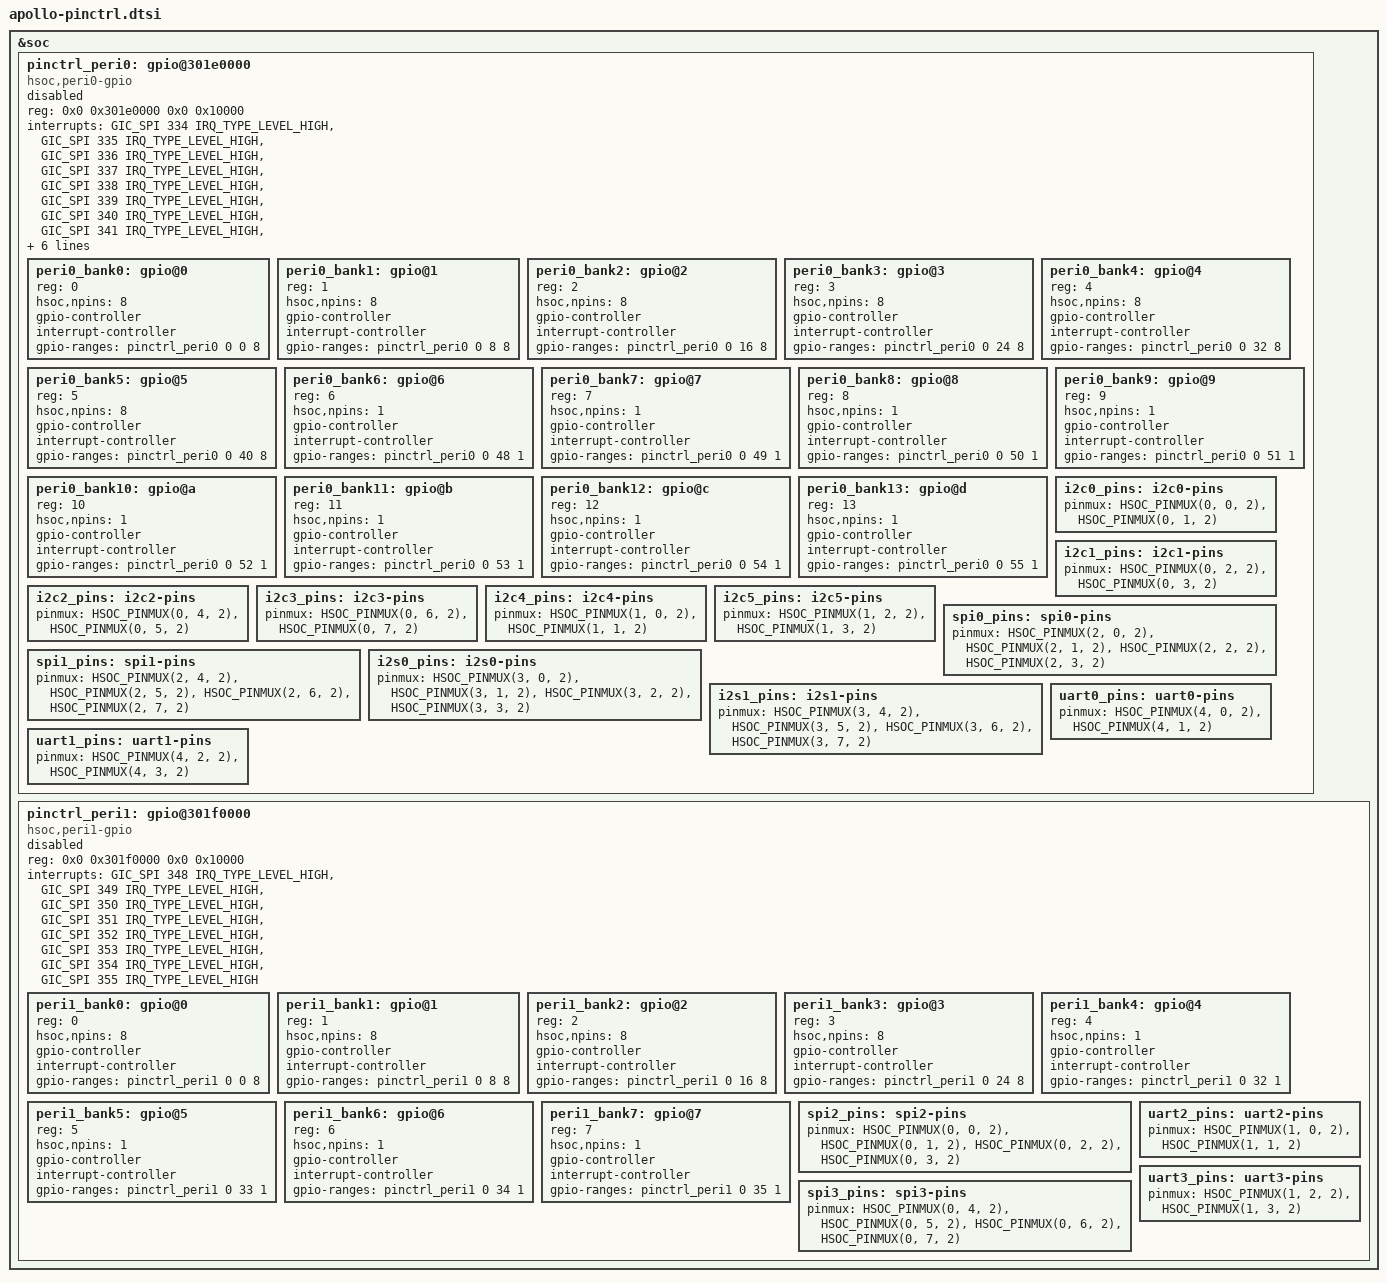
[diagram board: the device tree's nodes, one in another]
// SPDX-License-Identifier: (GPL-2.0 OR BSD-3-Clause)
/*
 * Copyright (c) 2025-2026, Arm Limited. All rights reserved.
 */

#include <dt-bindings/pinctrl/hsoc.h>

&soc {
	pinctrl_peri0: gpio@301e0000 {
		compatible = "hsoc,peri0-gpio";
		reg = <0x0 0x301e0000 0x0 0x10000>;
		interrupts = <GIC_SPI 334 IRQ_TYPE_LEVEL_HIGH>,
			     <GIC_SPI 335 IRQ_TYPE_LEVEL_HIGH>,
			     <GIC_SPI 336 IRQ_TYPE_LEVEL_HIGH>,
			     <GIC_SPI 337 IRQ_TYPE_LEVEL_HIGH>,
			     <GIC_SPI 338 IRQ_TYPE_LEVEL_HIGH>,
			     <GIC_SPI 339 IRQ_TYPE_LEVEL_HIGH>,
			     <GIC_SPI 340 IRQ_TYPE_LEVEL_HIGH>,
			     <GIC_SPI 341 IRQ_TYPE_LEVEL_HIGH>,
			     <GIC_SPI 342 IRQ_TYPE_LEVEL_HIGH>,
			     <GIC_SPI 343 IRQ_TYPE_LEVEL_HIGH>,
			     <GIC_SPI 344 IRQ_TYPE_LEVEL_HIGH>,
			     <GIC_SPI 345 IRQ_TYPE_LEVEL_HIGH>,
			     <GIC_SPI 346 IRQ_TYPE_LEVEL_HIGH>,
			     <GIC_SPI 347 IRQ_TYPE_LEVEL_HIGH>;
		#address-cells = <1>;
		#size-cells = <0>;
		status = "disabled";

		peri0_bank0: gpio@0 {
			reg = <0>;
			hsoc,npins = <8>;
			gpio-controller;
			#gpio-cells = <2>;
			interrupt-controller;
			#interrupt-cells = <2>;
			gpio-ranges = <&pinctrl_peri0 0 0 8>;
		};

		peri0_bank1: gpio@1 {
			reg = <1>;
			hsoc,npins = <8>;
			gpio-controller;
			#gpio-cells = <2>;
			interrupt-controller;
			#interrupt-cells = <2>;
			gpio-ranges = <&pinctrl_peri0 0 8 8>;
		};

		peri0_bank2: gpio@2 {
			reg = <2>;
			hsoc,npins = <8>;
			gpio-controller;
			#gpio-cells = <2>;
			interrupt-controller;
			#interrupt-cells = <2>;
			gpio-ranges = <&pinctrl_peri0 0 16 8>;
		};

		peri0_bank3: gpio@3 {
			reg = <3>;
			hsoc,npins = <8>;
			gpio-controller;
			#gpio-cells = <2>;
			interrupt-controller;
			#interrupt-cells = <2>;
			gpio-ranges = <&pinctrl_peri0 0 24 8>;
		};

		peri0_bank4: gpio@4 {
			reg = <4>;
			hsoc,npins = <8>;
			gpio-controller;
			#gpio-cells = <2>;
			interrupt-controller;
			#interrupt-cells = <2>;
			gpio-ranges = <&pinctrl_peri0 0 32 8>;
		};

		peri0_bank5: gpio@5 {
			reg = <5>;
			hsoc,npins = <8>;
			gpio-controller;
			#gpio-cells = <2>;
			interrupt-controller;
			#interrupt-cells = <2>;
			gpio-ranges = <&pinctrl_peri0 0 40 8>;
		};

		peri0_bank6: gpio@6 {
			reg = <6>;
			hsoc,npins = <1>;
			gpio-controller;
			#gpio-cells = <2>;
			interrupt-controller;
			#interrupt-cells = <2>;
			gpio-ranges = <&pinctrl_peri0 0 48 1>;
		};

		peri0_bank7: gpio@7 {
			reg = <7>;
			hsoc,npins = <1>;
			gpio-controller;
			#gpio-cells = <2>;
			interrupt-controller;
			#interrupt-cells = <2>;
			gpio-ranges = <&pinctrl_peri0 0 49 1>;
		};

		peri0_bank8: gpio@8 {
			reg = <8>;
			hsoc,npins = <1>;
			gpio-controller;
			#gpio-cells = <2>;
			interrupt-controller;
			#interrupt-cells = <2>;
			gpio-ranges = <&pinctrl_peri0 0 50 1>;
		};

		peri0_bank9: gpio@9 {
			reg = <9>;
			hsoc,npins = <1>;
			gpio-controller;
			#gpio-cells = <2>;
			interrupt-controller;
			#interrupt-cells = <2>;
			gpio-ranges = <&pinctrl_peri0 0 51 1>;
		};

		peri0_bank10: gpio@a {
			reg = <10>;
			hsoc,npins = <1>;
			gpio-controller;
			#gpio-cells = <2>;
			interrupt-controller;
			#interrupt-cells = <2>;
			gpio-ranges = <&pinctrl_peri0 0 52 1>;
		};

		peri0_bank11: gpio@b {
			reg = <11>;
			hsoc,npins = <1>;
			gpio-controller;
			#gpio-cells = <2>;
			interrupt-controller;
			#interrupt-cells = <2>;
			gpio-ranges = <&pinctrl_peri0 0 53 1>;
		};

		peri0_bank12: gpio@c {
			reg = <12>;
			hsoc,npins = <1>;
			gpio-controller;
			#gpio-cells = <2>;
			interrupt-controller;
			#interrupt-cells = <2>;
			gpio-ranges = <&pinctrl_peri0 0 54 1>;
		};

		peri0_bank13: gpio@d {
			reg = <13>;
			hsoc,npins = <1>;
			gpio-controller;
			#gpio-cells = <2>;
			interrupt-controller;
			#interrupt-cells = <2>;
			gpio-ranges = <&pinctrl_peri0 0 55 1>;
		};

		i2c0_pins: i2c0-pins {
			pinmux = <HSOC_PINMUX(0, 0, 2)>, <HSOC_PINMUX(0, 1, 2)>;
		};
		i2c1_pins: i2c1-pins {
			pinmux = <HSOC_PINMUX(0, 2, 2)>, <HSOC_PINMUX(0, 3, 2)>;
		};
		i2c2_pins: i2c2-pins {
			pinmux = <HSOC_PINMUX(0, 4, 2)>, <HSOC_PINMUX(0, 5, 2)>;
		};
		i2c3_pins: i2c3-pins {
			pinmux = <HSOC_PINMUX(0, 6, 2)>, <HSOC_PINMUX(0, 7, 2)>;
		};
		i2c4_pins: i2c4-pins {
			pinmux = <HSOC_PINMUX(1, 0, 2)>, <HSOC_PINMUX(1, 1, 2)>;
		};
		i2c5_pins: i2c5-pins {
			pinmux = <HSOC_PINMUX(1, 2, 2)>, <HSOC_PINMUX(1, 3, 2)>;
		};

		spi0_pins: spi0-pins {
			pinmux = <HSOC_PINMUX(2, 0, 2)>, <HSOC_PINMUX(2, 1, 2)>,
				 <HSOC_PINMUX(2, 2, 2)>, <HSOC_PINMUX(2, 3, 2)>;
		};
		spi1_pins: spi1-pins {
			pinmux = <HSOC_PINMUX(2, 4, 2)>, <HSOC_PINMUX(2, 5, 2)>,
				 <HSOC_PINMUX(2, 6, 2)>, <HSOC_PINMUX(2, 7, 2)>;
		};

		i2s0_pins: i2s0-pins {
			pinmux = <HSOC_PINMUX(3, 0, 2)>, <HSOC_PINMUX(3, 1, 2)>,
				 <HSOC_PINMUX(3, 2, 2)>, <HSOC_PINMUX(3, 3, 2)>;
		};

		i2s1_pins: i2s1-pins {
			pinmux = <HSOC_PINMUX(3, 4, 2)>, <HSOC_PINMUX(3, 5, 2)>,
				 <HSOC_PINMUX(3, 6, 2)>, <HSOC_PINMUX(3, 7, 2)>;
		};

		uart0_pins: uart0-pins {
			pinmux = <HSOC_PINMUX(4, 0, 2)>, <HSOC_PINMUX(4, 1, 2)>;
		};
		uart1_pins: uart1-pins {
			pinmux = <HSOC_PINMUX(4, 2, 2)>, <HSOC_PINMUX(4, 3, 2)>;
		};
	};

	pinctrl_peri1: gpio@301f0000 {
		compatible = "hsoc,peri1-gpio";
		reg = <0x0 0x301f0000 0x0 0x10000>;
		interrupts = <GIC_SPI 348 IRQ_TYPE_LEVEL_HIGH>,
			     <GIC_SPI 349 IRQ_TYPE_LEVEL_HIGH>,
			     <GIC_SPI 350 IRQ_TYPE_LEVEL_HIGH>,
			     <GIC_SPI 351 IRQ_TYPE_LEVEL_HIGH>,
			     <GIC_SPI 352 IRQ_TYPE_LEVEL_HIGH>,
			     <GIC_SPI 353 IRQ_TYPE_LEVEL_HIGH>,
			     <GIC_SPI 354 IRQ_TYPE_LEVEL_HIGH>,
			     <GIC_SPI 355 IRQ_TYPE_LEVEL_HIGH>;
		#address-cells = <1>;
		#size-cells = <0>;
		status = "disabled";

		peri1_bank0: gpio@0 {
			reg = <0>;
			hsoc,npins = <8>;
			gpio-controller;
			#gpio-cells = <2>;
			interrupt-controller;
			#interrupt-cells = <2>;
			gpio-ranges = <&pinctrl_peri1 0 0 8>;
		};

		peri1_bank1: gpio@1 {
			reg = <1>;
			hsoc,npins = <8>;
			gpio-controller;
			#gpio-cells = <2>;
			interrupt-controller;
			#interrupt-cells = <2>;
			gpio-ranges = <&pinctrl_peri1 0 8 8>;
		};

		peri1_bank2: gpio@2 {
			reg = <2>;
			hsoc,npins = <8>;
			gpio-controller;
			#gpio-cells = <2>;
			interrupt-controller;
			#interrupt-cells = <2>;
			gpio-ranges = <&pinctrl_peri1 0 16 8>;
		};

		peri1_bank3: gpio@3 {
			reg = <3>;
			hsoc,npins = <8>;
			gpio-controller;
			#gpio-cells = <2>;
			interrupt-controller;
			#interrupt-cells = <2>;
			gpio-ranges = <&pinctrl_peri1 0 24 8>;
		};

		peri1_bank4: gpio@4 {
			reg = <4>;
			hsoc,npins = <1>;
			gpio-controller;
			#gpio-cells = <2>;
			interrupt-controller;
			#interrupt-cells = <2>;
			gpio-ranges = <&pinctrl_peri1 0 32 1>;
		};

		peri1_bank5: gpio@5 {
			reg = <5>;
			hsoc,npins = <1>;
			gpio-controller;
			#gpio-cells = <2>;
			interrupt-controller;
			#interrupt-cells = <2>;
			gpio-ranges = <&pinctrl_peri1 0 33 1>;
		};

		peri1_bank6: gpio@6 {
			reg = <6>;
			hsoc,npins = <1>;
			gpio-controller;
			#gpio-cells = <2>;
			interrupt-controller;
			#interrupt-cells = <2>;
			gpio-ranges = <&pinctrl_peri1 0 34 1>;
		};

		peri1_bank7: gpio@7 {
			reg = <7>;
			hsoc,npins = <1>;
			gpio-controller;
			#gpio-cells = <2>;
			interrupt-controller;
			#interrupt-cells = <2>;
			gpio-ranges = <&pinctrl_peri1 0 35 1>;
		};

		spi2_pins: spi2-pins {
			pinmux = <HSOC_PINMUX(0, 0, 2)>, <HSOC_PINMUX(0, 1, 2)>,
				 <HSOC_PINMUX(0, 2, 2)>, <HSOC_PINMUX(0, 3, 2)>;
		};

		spi3_pins: spi3-pins {
			pinmux = <HSOC_PINMUX(0, 4, 2)>, <HSOC_PINMUX(0, 5, 2)>,
				 <HSOC_PINMUX(0, 6, 2)>, <HSOC_PINMUX(0, 7, 2)>;
		};

		uart2_pins: uart2-pins {
			pinmux = <HSOC_PINMUX(1, 0, 2)>, <HSOC_PINMUX(1, 1, 2)>;
		};

		uart3_pins: uart3-pins {
			pinmux = <HSOC_PINMUX(1, 2, 2)>, <HSOC_PINMUX(1, 3, 2)>;
		};
	};
};
